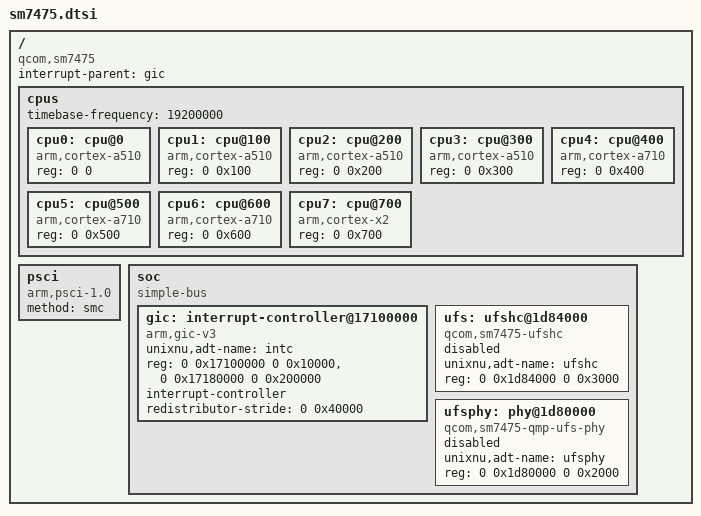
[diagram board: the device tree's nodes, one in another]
// SPDX-License-Identifier: BSD-2-Clause-Patent
// SM7475 (Snapdragon 7+ Gen 2). Layout follows UniXNU-sm8550-common's sm8550.dtsi; every value below was read
// from the marble downstream device tree (Mu-Silicium Resources/DTBs/marble.dtb) and the pmOS device tree of the phone.
/ {
    compatible = "qcom,sm7475";
    #address-cells = <2>;
    #size-cells = <2>;
    interrupt-parent = <&gic>;

    cpus {
        #address-cells = <2>;
        #size-cells = <0>;
        // arch timer clock-frequency 0x124f800 = 19.2 MHz in the downstream tree
        timebase-frequency = <19200000>;
        // MPIDR is core << 8 (marble-pmos MARBLE_PORT_CONTEXT.md): 4x A510, 3x A710, 1x X2.
        cpu0: cpu@0 { device_type = "cpu"; compatible = "arm,cortex-a510"; reg = <0 0>; };
        cpu1: cpu@100 { device_type = "cpu"; compatible = "arm,cortex-a510"; reg = <0 0x100>; };
        cpu2: cpu@200 { device_type = "cpu"; compatible = "arm,cortex-a510"; reg = <0 0x200>; };
        cpu3: cpu@300 { device_type = "cpu"; compatible = "arm,cortex-a510"; reg = <0 0x300>; };
        cpu4: cpu@400 { device_type = "cpu"; compatible = "arm,cortex-a710"; reg = <0 0x400>; };
        cpu5: cpu@500 { device_type = "cpu"; compatible = "arm,cortex-a710"; reg = <0 0x500>; };
        cpu6: cpu@600 { device_type = "cpu"; compatible = "arm,cortex-a710"; reg = <0 0x600>; };
        cpu7: cpu@700 { device_type = "cpu"; compatible = "arm,cortex-x2"; reg = <0 0x700>; };
    };

    psci { compatible = "arm,psci-1.0"; method = "smc"; };

    soc {
        compatible = "simple-bus";
        #address-cells = <2>;
        #size-cells = <2>;
        ranges;

        gic: interrupt-controller@17100000 {
            compatible = "arm,gic-v3";
            unixnu,adt-name = "intc";
            // GICD 0x17100000/0x10000, GICR 0x17180000/0x200000, stride 0x40000 (GICv4 frames)
            reg = <0 0x17100000 0 0x10000>, <0 0x17180000 0 0x200000>;
            #interrupt-cells = <4>;
            #address-cells = <0>;
            interrupt-controller;
            redistributor-stride = <0 0x40000>;
        };

        ufs: ufshc@1d84000 {
            compatible = "qcom,sm7475-ufshc";
            unixnu,adt-name = "ufshc";
            reg = <0 0x1d84000 0 0x3000>;
            status = "disabled";
        };

        ufsphy: phy@1d80000 {
            compatible = "qcom,sm7475-qmp-ufs-phy";
            unixnu,adt-name = "ufsphy";
            reg = <0 0x1d80000 0 0x2000>;
            status = "disabled";
        };
    };
};
